AUTOSAR XML (schema 4-2-2)
package /ComponentTypes
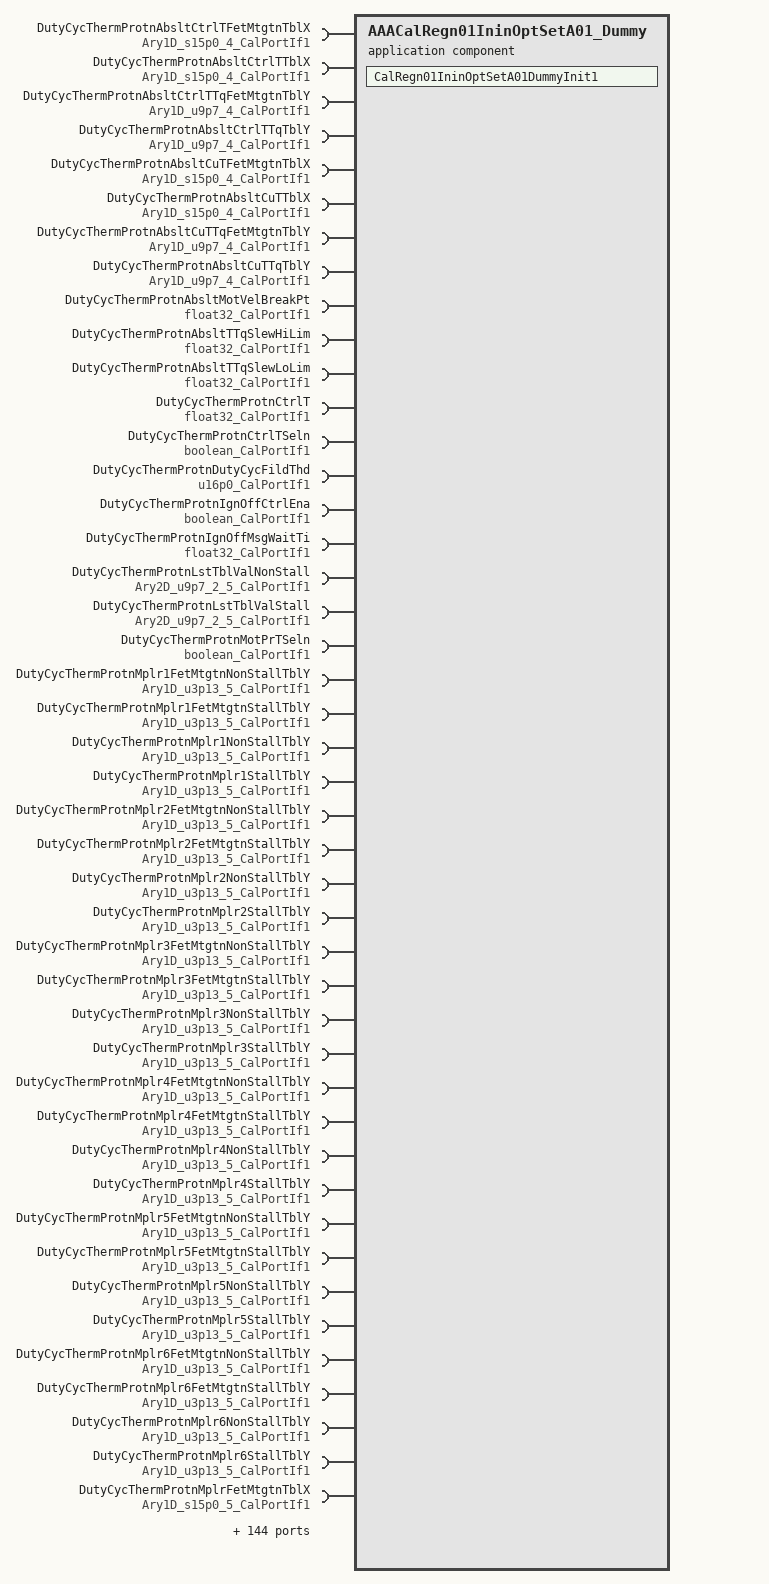
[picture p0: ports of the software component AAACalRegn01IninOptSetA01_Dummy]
  application sw component type AAACalRegn01IninOptSetA01_Dummy
    188 x require port:
      DutyCycThermProtnAbsltCtrlTFetMtgtnTblX: parameter-require-com-spec{init-value=[122, 123, 125, 127], parameter=Ary1D}, required-interface=Ary1D_s15p0_4_CalPortIf1
      DutyCycThermProtnAbsltCtrlTTblX: parameter-require-com-spec{init-value=[122, 123, 125, 127], parameter=Ary1D}, required-interface=Ary1D_s15p0_4_CalPortIf1
      DutyCycThermProtnAbsltCtrlTTqFetMtgtnTblY: parameter-require-com-spec{init-value=[346, 287, 234, 0], parameter=Ary1D}, required-interface=Ary1D_u9p7_4_CalPortIf1
      DutyCycThermProtnAbsltCtrlTTqTblY: parameter-require-com-spec{init-value=[346, 287, 234, 0], parameter=Ary1D}, required-interface=Ary1D_u9p7_4_CalPortIf1
      DutyCycThermProtnAbsltCuTFetMtgtnTblX: parameter-require-com-spec{init-value=[122, 123, 125, 127], parameter=Ary1D}, required-interface=Ary1D_s15p0_4_CalPortIf1
      DutyCycThermProtnAbsltCuTTblX: parameter-require-com-spec{init-value=[122, 123, 125, 127], parameter=Ary1D}, required-interface=Ary1D_s15p0_4_CalPortIf1
      DutyCycThermProtnAbsltCuTTqFetMtgtnTblY: parameter-require-com-spec{init-value=[346, 287, 234, 0], parameter=Ary1D}, required-interface=Ary1D_u9p7_4_CalPortIf1
      DutyCycThermProtnAbsltCuTTqTblY: parameter-require-com-spec{init-value=[346, 287, 234, 0], parameter=Ary1D}, required-interface=Ary1D_u9p7_4_CalPortIf1
      DutyCycThermProtnAbsltMotVelBreakPt: parameter-require-com-spec{init-value=1.375, parameter=Val}, required-interface=float32_CalPortIf1
      DutyCycThermProtnAbsltTTqSlewHiLim: parameter-require-com-spec{init-value=0.3, parameter=Val}, required-interface=float32_CalPortIf1
      DutyCycThermProtnAbsltTTqSlewLoLim: parameter-require-com-spec{init-value=0.3, parameter=Val}, required-interface=float32_CalPortIf1
      DutyCycThermProtnCtrlT: parameter-require-com-spec{init-value=70, parameter=Val}, required-interface=float32_CalPortIf1
      DutyCycThermProtnCtrlTSeln: parameter-require-com-spec{init-value=1, parameter=Logl}, required-interface=boolean_CalPortIf1
      DutyCycThermProtnDutyCycFildThd: parameter-require-com-spec{init-value=92, parameter=Val}, required-interface=u16p0_CalPortIf1
      DutyCycThermProtnIgnOffCtrlEna: parameter-require-com-spec{init-value=0, parameter=Logl}, required-interface=boolean_CalPortIf1
      DutyCycThermProtnIgnOffMsgWaitTi: parameter-require-com-spec{init-value=0.5, parameter=Val}, required-interface=float32_CalPortIf1
      DutyCycThermProtnLstTblValNonStall: parameter-require-com-spec{init-value=[[128, 128, 128, 44, 44], [128, 128, 128, 44, 44]], parameter=Ary2D}, required-interface=Ary2D_u9p7_2_5_CalPortIf1
      DutyCycThermProtnLstTblValStall: parameter-require-com-spec{init-value=[[124, 124, 124, 40, 40], [124, 124, 124, 40, 40]], parameter=Ary2D}, required-interface=Ary2D_u9p7_2_5_CalPortIf1
      DutyCycThermProtnMotPrTSeln: parameter-require-com-spec{init-value=1, parameter=Logl}, required-interface=boolean_CalPortIf1
      DutyCycThermProtnMplr1FetMtgtnNonStallTblY: parameter-require-com-spec{init-value=[127, 127, 127, 1630, 1630], parameter=Ary1D}, required-interface=Ary1D_u3p13_5_CalPortIf1
      DutyCycThermProtnMplr1FetMtgtnStallTblY: parameter-require-com-spec{init-value=[133, 133, 133, 180, 180], parameter=Ary1D}, required-interface=Ary1D_u3p13_5_CalPortIf1
      DutyCycThermProtnMplr1NonStallTblY: parameter-require-com-spec{init-value=[127, 127, 127, 1630, 1630], parameter=Ary1D}, required-interface=Ary1D_u3p13_5_CalPortIf1
      DutyCycThermProtnMplr1StallTblY: parameter-require-com-spec{init-value=[133, 133, 133, 180, 180], parameter=Ary1D}, required-interface=Ary1D_u3p13_5_CalPortIf1
      DutyCycThermProtnMplr2FetMtgtnNonStallTblY: parameter-require-com-spec{init-value=[159, 159, 159, 281, 281], parameter=Ary1D}, required-interface=Ary1D_u3p13_5_CalPortIf1
      DutyCycThermProtnMplr2FetMtgtnStallTblY: parameter-require-com-spec{init-value=[167, 167, 167, 310, 310], parameter=Ary1D}, required-interface=Ary1D_u3p13_5_CalPortIf1
      DutyCycThermProtnMplr2NonStallTblY: parameter-require-com-spec{init-value=[159, 159, 159, 281, 281], parameter=Ary1D}, required-interface=Ary1D_u3p13_5_CalPortIf1
      DutyCycThermProtnMplr2StallTblY: parameter-require-com-spec{init-value=[167, 167, 167, 310, 310], parameter=Ary1D}, required-interface=Ary1D_u3p13_5_CalPortIf1
      DutyCycThermProtnMplr3FetMtgtnNonStallTblY: parameter-require-com-spec{init-value=[199, 199, 199, 1282, 1282], parameter=Ary1D}, required-interface=Ary1D_u3p13_5_CalPortIf1
      DutyCycThermProtnMplr3FetMtgtnStallTblY: parameter-require-com-spec{init-value=[210, 210, 210, 1707, 1707], parameter=Ary1D}, required-interface=Ary1D_u3p13_5_CalPortIf1
      DutyCycThermProtnMplr3NonStallTblY: parameter-require-com-spec{init-value=[199, 199, 199, 1282, 1282], parameter=Ary1D}, required-interface=Ary1D_u3p13_5_CalPortIf1
      DutyCycThermProtnMplr3StallTblY: parameter-require-com-spec{init-value=[210, 210, 210, 1707, 1707], parameter=Ary1D}, required-interface=Ary1D_u3p13_5_CalPortIf1
      DutyCycThermProtnMplr4FetMtgtnNonStallTblY: parameter-require-com-spec{init-value=5 x 1, parameter=Ary1D}, required-interface=Ary1D_u3p13_5_CalPortIf1
      DutyCycThermProtnMplr4FetMtgtnStallTblY: parameter-require-com-spec{init-value=5 x 1, parameter=Ary1D}, required-interface=Ary1D_u3p13_5_CalPortIf1
      DutyCycThermProtnMplr4NonStallTblY: parameter-require-com-spec{init-value=5 x 1, parameter=Ary1D}, required-interface=Ary1D_u3p13_5_CalPortIf1
      DutyCycThermProtnMplr4StallTblY: parameter-require-com-spec{init-value=5 x 1, parameter=Ary1D}, required-interface=Ary1D_u3p13_5_CalPortIf1
      DutyCycThermProtnMplr5FetMtgtnNonStallTblY: parameter-require-com-spec{init-value=[998, 998, 998, 9535, 9535], parameter=Ary1D}, required-interface=Ary1D_u3p13_5_CalPortIf1
      DutyCycThermProtnMplr5FetMtgtnStallTblY: parameter-require-com-spec{init-value=[998, 998, 998, 9535, 9535], parameter=Ary1D}, required-interface=Ary1D_u3p13_5_CalPortIf1
      DutyCycThermProtnMplr5NonStallTblY: parameter-require-com-spec{init-value=[998, 998, 998, 9535, 9535], parameter=Ary1D}, required-interface=Ary1D_u3p13_5_CalPortIf1
      DutyCycThermProtnMplr5StallTblY: parameter-require-com-spec{init-value=[998, 998, 998, 9535, 9535], parameter=Ary1D}, required-interface=Ary1D_u3p13_5_CalPortIf1
      DutyCycThermProtnMplr6FetMtgtnNonStallTblY: parameter-require-com-spec{init-value=5 x 1, parameter=Ary1D}, required-interface=Ary1D_u3p13_5_CalPortIf1
      DutyCycThermProtnMplr6FetMtgtnStallTblY: parameter-require-com-spec{init-value=5 x 1, parameter=Ary1D}, required-interface=Ary1D_u3p13_5_CalPortIf1
      DutyCycThermProtnMplr6NonStallTblY: parameter-require-com-spec{init-value=5 x 1, parameter=Ary1D}, required-interface=Ary1D_u3p13_5_CalPortIf1
      DutyCycThermProtnMplr6StallTblY: parameter-require-com-spec{init-value=5 x 1, parameter=Ary1D}, required-interface=Ary1D_u3p13_5_CalPortIf1
      DutyCycThermProtnMplrFetMtgtnTblX: parameter-require-com-spec{init-value=[-40, 0, 83, 84, 85], parameter=Ary1D}, required-interface=Ary1D_s15p0_5_CalPortIf1
      DutyCycThermProtnMplrTblX: parameter-require-com-spec{init-value=[-40, 0, 83, 84, 85], parameter=Ary1D}, required-interface=Ary1D_s15p0_5_CalPortIf1
      DutyCycThermProtnMplrTSeln: parameter-require-com-spec{init-value=1, parameter=Logl}, required-interface=boolean_CalPortIf1
      DutyCycThermProtnSlowFilTSeln: parameter-require-com-spec{init-value=0, parameter=Logl}, required-interface=boolean_CalPortIf1
      DutyCycThermProtnThermLimScaFac: parameter-require-com-spec{init-value=0.5, parameter=Val}, required-interface=float32_CalPortIf1
      DutyCycThermProtnThermLoadLimTblX: parameter-require-com-spec{init-value=[[0, 76, 80, 84, 88, 92, 96, 100], [0, 76, 80, 84, 88, 92, 96, 100]], parameter=Ary2D}, required-interface=Ary2D_u16p0_2_8_CalPortIf1
      DutyCycThermProtnThermLoadLimTblY: parameter-require-com-spec{init-value=[[346, 346, 346, 346, 287, 234, 181, 128], [346, 346, 346, 346, 287, 234, 181, 128]], parameter=Ary2D}, required-interface=Ary2D_u9p7_2_8_CalPortIf1
      DutyCycThermProtnTqCmdSlewDwn: parameter-require-com-spec{init-value=0.3, parameter=Val}, required-interface=float32_CalPortIf1
      DutyCycThermProtnTqCmdSlewUp: parameter-require-com-spec{init-value=0.3, parameter=Val}, required-interface=float32_CalPortIf1
      HiLoadStallLimrMotVelMgnThd: parameter-require-com-spec{init-value=[1.375, 1.375], parameter=Ary1D}, required-interface=Ary1D_f32_2_CalPortIf1
      HiLoadStallLimrStallMotTqCmdFetMtgtnLimX: parameter-require-com-spec{init-value=[0, 563, 640, 717, 768, 768], parameter=Ary1D}, required-interface=Ary1D_u8p8_6_CalPortIf1
      HiLoadStallLimrStallMotTqCmdFetMtgtnLimY: parameter-require-com-spec{init-value=[768, 768, 512, 256, 0, 0], parameter=Ary1D}, required-interface=Ary1D_u8p8_6_CalPortIf1
      HiLoadStallLimrStallMotTqCmdLimX: parameter-require-com-spec{init-value=[0, 563, 640, 717, 768, 768], parameter=Ary1D}, required-interface=Ary1D_u8p8_6_CalPortIf1
      HiLoadStallLimrStallMotTqCmdLimY: parameter-require-com-spec{init-value=[768, 768, 512, 256, 0, 0], parameter=Ary1D}, required-interface=Ary1D_u8p8_6_CalPortIf1
      HiLoadStallLimrStallMotTqLimSlewRate: parameter-require-com-spec{init-value=[0.101563, 0.101563], parameter=Ary1D}, required-interface=Ary1D_f32_2_CalPortIf1
      HiLoadStallLimrStallThermLimSca: parameter-require-com-spec{init-value=0.5, parameter=Val}, required-interface=float32_CalPortIf1
      LrndRackCentrMotTqThd: parameter-require-com-spec{init-value=2.8, parameter=Val}, required-interface=float32_CalPortIf1
      LrndRackCentrMotVelThd: parameter-require-com-spec{init-value=25, parameter=Val}, required-interface=float32_CalPortIf1
      MotCtrlPrmEstimnFetRNom: parameter-require-com-spec{init-value=0.0052, parameter=Val}, required-interface=float32_CalPortIf1
      MotCtrlPrmEstimnMotBackEmfConHiLim: parameter-require-com-spec{init-value=0.045, parameter=Val}, required-interface=float32_CalPortIf1
      MotCtrlPrmEstimnMotBackEmfConLoLim: parameter-require-com-spec{init-value=0.031, parameter=Val}, required-interface=float32_CalPortIf1
      MotCtrlPrmEstimnMotBackEmfConNom: parameter-require-com-spec{init-value=0.04, parameter=Val}, required-interface=float32_CalPortIf1
      MotCtrlPrmEstimnMotBackEmfConSatnScaIvtrLoaMtgtn: parameter-require-com-spec{init-value=1, parameter=Val}, required-interface=float32_CalPortIf1
      MotCtrlPrmEstimnMotBackEmfConSatnX: parameter-require-com-spec{init-value=[0, 1280, 2560, 3840, 5120, 6400, 7680, 8960, 10240, 11520, 12800, 14080, 15360, 16640, 19200, 21760], parameter=Ary1D}, required-interface=Ary1D_u9p7_16_CalPortIf1
      MotCtrlPrmEstimnMotBackEmfConSatnY: parameter-require-com-spec{init-value=[16384, 16384, 16384, 16384, 16384, 16384, 16384, 16384, 16384, 16384, 16384, 16370, 16336, 16276, 16095, 15869], parameter=Ary1D}, required-interface=Ary1D_u2p14_16_CalPortIf1
      MotCtrlPrmEstimnMotCurrDaxInduSatnBilnrSeln: parameter-require-com-spec{init-value=[0, 3200, 6400, 9600, 12800, 16000], parameter=Ary1D}, required-interface=Ary1D_u9p7_6_CalPortIf1
      MotCtrlPrmEstimnMotCurrQaxInduSatnX: parameter-require-com-spec{init-value=[0, 3200, 6400, 9600, 12800, 16000, 19200], parameter=Ary1D}, required-interface=Ary1D_u9p7_7_CalPortIf1
      MotCtrlPrmEstimnMotInduDaxHiLim: parameter-require-com-spec{init-value=0.00013, parameter=Val}, required-interface=float32_CalPortIf1
      MotCtrlPrmEstimnMotInduDaxIvtrLoaMtgtn: parameter-require-com-spec{init-value=0.00013, parameter=Val}, required-interface=float32_CalPortIf1
      MotCtrlPrmEstimnMotInduDaxLoLim: parameter-require-com-spec{init-value=0.0001, parameter=Val}, required-interface=float32_CalPortIf1
      MotCtrlPrmEstimnMotInduDaxNom: parameter-require-com-spec{init-value=0.00011889, parameter=Val}, required-interface=float32_CalPortIf1
      MotCtrlPrmEstimnMotInduDaxSatnScaY: parameter-require-com-spec{init-value=6 x [16384, 16384, 16384, 16384, 16384, 16305, 16096], parameter=Ary2D}, required-interface=Ary2D_u2p14_6_7_CalPortIf1
      MotCtrlPrmEstimnMotInduQaxHiLim: parameter-require-com-spec{init-value=0.00013, parameter=Val}, required-interface=float32_CalPortIf1
      MotCtrlPrmEstimnMotInduQaxIvtrLoaMtgtn: parameter-require-com-spec{init-value=0.00013, parameter=Val}, required-interface=float32_CalPortIf1
      MotCtrlPrmEstimnMotInduQaxLoLim: parameter-require-com-spec{init-value=0.0001, parameter=Val}, required-interface=float32_CalPortIf1
      MotCtrlPrmEstimnMotInduQaxNom: parameter-require-com-spec{init-value=0.00011889, parameter=Val}, required-interface=float32_CalPortIf1
      MotCtrlPrmEstimnMotInduQaxSatnScaY: parameter-require-com-spec{init-value=6 x [16384, 16384, 16384, 16384, 16384, 16305, 16096], parameter=Ary2D}, required-interface=Ary2D_u2p14_6_7_CalPortIf1
      MotCtrlPrmEstimnMotRHiLim: parameter-require-com-spec{init-value=0.032, parameter=Val}, required-interface=float32_CalPortIf1
      MotCtrlPrmEstimnMotRLoLim: parameter-require-com-spec{init-value=0.01246, parameter=Val}, required-interface=float32_CalPortIf1
      MotCtrlPrmEstimnMotRNom: parameter-require-com-spec{init-value=0.0139, parameter=Val}, required-interface=float32_CalPortIf1
      MotCtrlPrmEstimnMotWidgThermCoeff: parameter-require-com-spec{init-value=0.0039, parameter=Val}, required-interface=float32_CalPortIf1
      MotCtrlPrmEstimnTNom: parameter-require-com-spec{init-value=25, parameter=Val}, required-interface=float32_CalPortIf1
      MotCurrPeakEstimnCurrFilFrq: parameter-require-com-spec{init-value=8, parameter=Val}, required-interface=float32_CalPortIf1
      MotCurrPeakEstimnCurrPeakEstimdFilFrq: parameter-require-com-spec{init-value=0.03, parameter=Val}, required-interface=float32_CalPortIf1
      MotCurrRegCfgMotClsdLoopBwDaxY: parameter-require-com-spec{init-value=[12800, 19200, 19200, 19200], parameter=Ary1D}, required-interface=Ary1D_u10p6_4_CalPortIf1
      MotCurrRegCfgMotClsdLoopBwQaxY: parameter-require-com-spec{init-value=[12800, 19200, 19200, 19200], parameter=Ary1D}, required-interface=Ary1D_u10p6_4_CalPortIf1
      MotCurrRegCfgMotDampgRatDax: parameter-require-com-spec{init-value=1, parameter=Val}, required-interface=float32_CalPortIf1
      MotCurrRegCfgMotDampgRatQax: parameter-require-com-spec{init-value=1, parameter=Val}, required-interface=float32_CalPortIf1
      MotCurrRegCfgMotNatFrqDaxY: parameter-require-com-spec{init-value=[38400, 38400, 38400, 38400], parameter=Ary1D}, required-interface=Ary1D_u9p7_4_CalPortIf1
      MotCurrRegCfgMotNatFrqQaxY: parameter-require-com-spec{init-value=[38400, 38400, 38400, 38400], parameter=Ary1D}, required-interface=Ary1D_u9p7_4_CalPortIf1
      MotCurrRegCfgMotRVirtDax: parameter-require-com-spec{init-value=0, parameter=Val}, required-interface=float32_CalPortIf1
      MotCurrRegCfgMotRVirtQax: parameter-require-com-spec{init-value=0, parameter=Val}, required-interface=float32_CalPortIf1
      MotCurrRegCfgMotVelFilFrq: parameter-require-com-spec{init-value=10, parameter=Val}, required-interface=float32_CalPortIf1
      MotCurrRegVltgLimrCurrLoaScarSlewRate: parameter-require-com-spec{init-value=100, parameter=Val}, required-interface=float32_CalPortIf1
      MotCurrRegVltgLimrDaxAntiWdupCoeff: parameter-require-com-spec{init-value=0, parameter=Val}, required-interface=float32_CalPortIf1
      MotCurrRegVltgLimrDualEcuLoaScarSlewRate: parameter-require-com-spec{init-value=100, parameter=Val}, required-interface=float32_CalPortIf1
      MotCurrRegVltgLimrFETLoaScarSlewRate: parameter-require-com-spec{init-value=100, parameter=Val}, required-interface=float32_CalPortIf1
      MotCurrRegVltgLimrIvtrLoaScarSlewRate: parameter-require-com-spec{init-value=100, parameter=Val}, required-interface=float32_CalPortIf1
      MotCurrRegVltgLimrMotVltgBrdgLpFilFrq: parameter-require-com-spec{init-value=200, parameter=Val}, required-interface=float32_CalPortIf1
      MotCurrRegVltgLimrMotVltgDaxIntglHiLim: parameter-require-com-spec{init-value=9, parameter=Val}, required-interface=float32_CalPortIf1
      MotCurrRegVltgLimrMotVltgDaxIntglLoLim: parameter-require-com-spec{init-value=-4.5, parameter=Val}, required-interface=float32_CalPortIf1
      MotCurrRegVltgLimrMotVltgQaxFfLpFilFrq: parameter-require-com-spec{init-value=500, parameter=Val}, required-interface=float32_CalPortIf1
      MotCurrRegVltgLimrMotVltgQaxIntglHiLim: parameter-require-com-spec{init-value=14.5, parameter=Val}, required-interface=float32_CalPortIf1
      MotCurrRegVltgLimrMotVltgQaxIntglLoLim: parameter-require-com-spec{init-value=-14.5, parameter=Val}, required-interface=float32_CalPortIf1
      MotCurrRegVltgLimrQaxAntiWdupCoeff: parameter-require-com-spec{init-value=0, parameter=Val}, required-interface=float32_CalPortIf1
      MotCurrRegVltgLimrQaxAntiWdupScagDi: parameter-require-com-spec{init-value=0, parameter=Logl}, required-interface=boolean_CalPortIf1
      MotRefMdlCurrDaxBoostGain: parameter-require-com-spec{init-value=0, parameter=Val}, required-interface=float32_CalPortIf1
      MotRefMdlCurrDaxBoostTqScaX: parameter-require-com-spec{init-value=[0, 6144, 7168, 8192, 9216, 10240, 12288, 14336, 16384, 18432, 20480], parameter=Ary1D}, required-interface=Ary1D_u4p12_11_CalPortIf1
      MotRefMdlCurrDaxBoostTqScaY: parameter-require-com-spec{init-value=[0, 16384, 19661, 22938, 23757, 25395, 27034, 27853, 29491, 31130, 32768], parameter=Ary1D}, required-interface=Ary1D_u1p15_11_CalPortIf1
      MotRefMdlCurrDaxQaxRefDelta: parameter-require-com-spec{init-value=[-3.1415927, -2.3561945, -1.5707964, -0.7853982, 0, 0.7853982, 1.5707964, 2.3561945], parameter=Ary1D}, required-interface=Ary1D_f32_8_CalPortIf1
      MotRefMdlCurrItrnTolr: parameter-require-com-spec{init-value=0.1, parameter=Val}, required-interface=float32_CalPortIf1
      MotRefMdlMotCurrDaxMaxSca: parameter-require-com-spec{init-value=1, parameter=Val}, required-interface=float32_CalPortIf1
      MotRefMdlQuad13VltgSdlX: parameter-require-com-spec{init-value=[0, 3200, 6400, 9600, 16000, 19200, 22400, 25600, 28800, 35200], parameter=Ary1D}, required-interface=Ary1D_u11p5_10_CalPortIf1
      MotRefMdlQuad13VltgSdlY: parameter-require-com-spec{init-value=10 x 0, parameter=Ary1D}, required-interface=Ary1D_u3p13_10_CalPortIf1
      MotRefMdlQuad24VltgSdlX: parameter-require-com-spec{init-value=[0, 3200, 6400, 9600, 16000, 19200, 22400, 25600, 28800, 35200], parameter=Ary1D}, required-interface=Ary1D_u11p5_10_CalPortIf1
      MotRefMdlQuad24VltgSdlY: parameter-require-com-spec{init-value=10 x 0, parameter=Ary1D}, required-interface=Ary1D_u3p13_10_CalPortIf1
      MotRefMdlVltgOverRThdSca: parameter-require-com-spec{init-value=0.25, parameter=Val}, required-interface=float32_CalPortIf1
      MotTqTranlDampgCmdLim: parameter-require-com-spec{init-value=3, parameter=Val}, required-interface=float32_CalPortIf1
      MotTqTranlDampgVelThd: parameter-require-com-spec{init-value=2.3, parameter=Val}, required-interface=float32_CalPortIf1
      PwrLimrAssiRednLpFilFrq: parameter-require-com-spec{init-value=0.365, parameter=Val}, required-interface=float32_CalPortIf1
      PwrLimrBackEmfConStdT: parameter-require-com-spec{init-value=0.0335999, parameter=Val}, required-interface=float32_CalPortIf1
      PwrLimrBrdgVltgAdjSlew: parameter-require-com-spec{init-value=0.5, parameter=Val}, required-interface=float32_CalPortIf1
      PwrLimrBrdgVltgAltFltAdj: parameter-require-com-spec{init-value=1, parameter=Val}, required-interface=float32_CalPortIf1
      PwrLimrFilAssiRednThd: parameter-require-com-spec{init-value=0.6, parameter=Val}, required-interface=float32_CalPortIf1
      PwrLimrLoVoltAssiRcvrThd: parameter-require-com-spec{init-value=13.5, parameter=Val}, required-interface=float32_CalPortIf1
      PwrLimrLoVoltAssiRcvrTi: parameter-require-com-spec{init-value=2000, parameter=Val}, required-interface=uint16_CalPortIf1
      PwrLimrMotEnvlpX: parameter-require-com-spec{init-value=[-17600, -12800, -10400, -8800, -5657, -4600, -3499, -1731, 0, 1731, 3499, 4600, 5657, 8800], parameter=Ary1D}, required-interface=Ary1D_s11p4_14_CalPortIf1
      PwrLimrMotEnvlpY: parameter-require-com-spec{init-value=[1475, 2867, 3891, 4710, 7168, 8397, 9486, 9486, 9486, 9486, 7277, 5994, 4506, 0], parameter=Ary1D}, required-interface=Ary1D_u5p11_14_CalPortIf1
      PwrLimrMotVelLpFilFrq: parameter-require-com-spec{init-value=100, parameter=Val}, required-interface=float32_CalPortIf1
      PwrLimrSpdAdjSlewDec: parameter-require-com-spec{init-value=3.125, parameter=Val}, required-interface=float32_CalPortIf1
      PwrLimrSpdAdjSlewEna: parameter-require-com-spec{init-value=1, parameter=Logl}, required-interface=boolean_CalPortIf1
      PwrLimrSpdAdjSlewInc: parameter-require-com-spec{init-value=3125, parameter=Val}, required-interface=float32_CalPortIf1
      PwrLimrStdOperMotEnvlpX: parameter-require-com-spec{init-value=[0, 2182, 5717, 7919, 10034, 16320], parameter=Ary1D}, required-interface=Ary1D_u11p5_6_CalPortIf1
      PwrLimrStdOperMotEnvlpY: parameter-require-com-spec{init-value=[18973, 18973, 14553, 11989, 9011, 0], parameter=Ary1D}, required-interface=Ary1D_u4p12_6_CalPortIf1
      PwrLimrVltgDptMotVelOffsX: parameter-require-com-spec{init-value=[17496, 18728, 18928, 19136, 19336, 19544, 20568, 21592, 22208, 25280], parameter=Ary1D}, required-interface=Ary1D_u5p11_10_CalPortIf1
      PwrLimrVltgDptMotVelOffsY: parameter-require-com-spec{init-value=[3395, 2859, 2769, 2680, 2591, 2501, 2054, 1608, 1340, 0], parameter=Ary1D}, required-interface=Ary1D_u11p5_10_CalPortIf1
      SysGlbPrmSysTqRat: parameter-require-com-spec{init-value=20, parameter=Val}, required-interface=float32_CalPortIf1
      TEstimnAmbPwrMplr: parameter-require-com-spec{init-value=[0.01, 0.01, 0.01], parameter=Ary1D}, required-interface=Ary1D_f32_3_CalPortIf1
      TEstimnAmbTSca: parameter-require-com-spec{init-value=[0.9, 0.9, 0.9], parameter=Ary1D}, required-interface=Ary1D_f32_3_CalPortIf1
      TEstimnAssiMechAmbLpFilFrq: parameter-require-com-spec{init-value=0.024, parameter=Val}, required-interface=float32_CalPortIf1
      TEstimnAssiMechAmbLpFilFrqDualEcuFltMtgtn: parameter-require-com-spec{init-value=0.024, parameter=Val}, required-interface=float32_CalPortIf1
      TEstimnAssiMechAmbLpFilFrqFetMtgtnEna: parameter-require-com-spec{init-value=0.024, parameter=Val}, required-interface=float32_CalPortIf1
      TEstimnAssiMechAmbMplr: parameter-require-com-spec{init-value=[0.01, 0.01, 0.01], parameter=Ary1D}, required-interface=Ary1D_f32_3_CalPortIf1
      TEstimnAssiMechCorrLim: parameter-require-com-spec{init-value=[60, 60, 60], parameter=Ary1D}, required-interface=Ary1D_f32_3_CalPortIf1
      TEstimnAssiMechDampgSca: parameter-require-com-spec{init-value=[0.0001, 0.0001, 0.0001], parameter=Ary1D}, required-interface=Ary1D_f32_3_CalPortIf1
      TEstimnAssiMechDftT: parameter-require-com-spec{init-value=[50, 50, 50], parameter=Ary1D}, required-interface=Ary1D_f32_3_CalPortIf1
      TEstimnAssiMechLLFilCoeffA1: parameter-require-com-spec{init-value=[0.99996858, 0.99996858, 0.99996858], parameter=Ary1D}, required-interface=Ary1D_f32_3_CalPortIf1
      TEstimnAssiMechLLFilCoeffB0: parameter-require-com-spec{init-value=[0.4761987, 0.4761987, 0.4761987], parameter=Ary1D}, required-interface=Ary1D_f32_3_CalPortIf1
      TEstimnAssiMechLLFilCoeffB1: parameter-require-com-spec{init-value=[-0.4761673, -0.4761673, -0.4761673], parameter=Ary1D}, required-interface=Ary1D_f32_3_CalPortIf1
      TEstimnAssiMechSlew: parameter-require-com-spec{init-value=[1, 1, 1], parameter=Ary1D}, required-interface=Ary1D_f32_3_CalPortIf1
      TEstimnCorrnTAssiMech: parameter-require-com-spec{init-value=[0, 0, 0], parameter=Ary1D}, required-interface=Ary1D_f32_3_CalPortIf1
      TEstimnCorrnTCu: parameter-require-com-spec{init-value=[0, 0, 0], parameter=Ary1D}, required-interface=Ary1D_f32_3_CalPortIf1
      TEstimnCorrnTMag: parameter-require-com-spec{init-value=[0, 0, 0], parameter=Ary1D}, required-interface=Ary1D_f32_3_CalPortIf1
      TEstimnCorrnTSi: parameter-require-com-spec{init-value=[0, 0, 0], parameter=Ary1D}, required-interface=Ary1D_f32_3_CalPortIf1
      TEstimnCuAmbLpFilFrq: parameter-require-com-spec{init-value=0.024, parameter=Val}, required-interface=float32_CalPortIf1
      TEstimnCuAmbLpFilFrqDualEcuFltMtgtn: parameter-require-com-spec{init-value=0.024, parameter=Val}, required-interface=float32_CalPortIf1
      TEstimnCuAmbLpFilFrqFetMtgtnEna: parameter-require-com-spec{init-value=0.024, parameter=Val}, required-interface=float32_CalPortIf1
      TEstimnCuAmbMplr: parameter-require-com-spec{init-value=[0.75, 0.75, 0.75], parameter=Ary1D}, required-interface=Ary1D_f32_3_CalPortIf1
      TEstimnCuCorrnLim: parameter-require-com-spec{init-value=[80, 80, 80], parameter=Ary1D}, required-interface=Ary1D_f32_3_CalPortIf1
      TEstimnCuLLFilCoeffA1: parameter-require-com-spec{init-value=[0.999943, 0.999943, 0.999943], parameter=Ary1D}, required-interface=Ary1D_f32_3_CalPortIf1
      TEstimnCuLLFilCoeffB0: parameter-require-com-spec{init-value=[0.86667, 0.86667, 0.86667], parameter=Ary1D}, required-interface=Ary1D_f32_3_CalPortIf1
      TEstimnCuLLFilCoeffB1: parameter-require-com-spec{init-value=[-0.866613, -0.866613, -0.866613], parameter=Ary1D}, required-interface=Ary1D_f32_3_CalPortIf1
      TEstimnEngTSca: parameter-require-com-spec{init-value=[0.1, 0.1, 0.1], parameter=Ary1D}, required-interface=Ary1D_f32_3_CalPortIf1
      TEstimnMagAmbLpFilFrq: parameter-require-com-spec{init-value=0.024, parameter=Val}, required-interface=float32_CalPortIf1
      TEstimnMagAmbLpFilFrqDualEcuFltMtgtn: parameter-require-com-spec{init-value=0.024, parameter=Val}, required-interface=float32_CalPortIf1
      TEstimnMagAmbLpFilFrqFetMtgtnEna: parameter-require-com-spec{init-value=0.024, parameter=Val}, required-interface=float32_CalPortIf1
      TEstimnMagAmbMplr: parameter-require-com-spec{init-value=[0.01, 0.01, 0.01], parameter=Ary1D}, required-interface=Ary1D_f32_3_CalPortIf1
      TEstimnMagCorrnLim: parameter-require-com-spec{init-value=[60, 60, 60], parameter=Ary1D}, required-interface=Ary1D_f32_3_CalPortIf1
      TEstimnMagLLFilCoeffA1: parameter-require-com-spec{init-value=[0.999962, 0.999962, 0.999962], parameter=Ary1D}, required-interface=Ary1D_f32_3_CalPortIf1
      TEstimnMagLLFilCoeffB0: parameter-require-com-spec{init-value=[0.571437, 0.571437, 0.571437], parameter=Ary1D}, required-interface=Ary1D_f32_3_CalPortIf1
      TEstimnMagLLFilCoeffB1: parameter-require-com-spec{init-value=[-0.571399, -0.571399, -0.571399], parameter=Ary1D}, required-interface=Ary1D_f32_3_CalPortIf1
      TEstimnSiAmbLpFilFrq: parameter-require-com-spec{init-value=0.024, parameter=Val}, required-interface=float32_CalPortIf1
      TEstimnSiAmbLpFilFrqDualEcuFltMtgtn: parameter-require-com-spec{init-value=0.024, parameter=Val}, required-interface=float32_CalPortIf1
      TEstimnSiAmbLpFilFrqFetMtgtnEna: parameter-require-com-spec{init-value=0.024, parameter=Val}, required-interface=float32_CalPortIf1
      TEstimnSiAmbMplr: parameter-require-com-spec{init-value=[0, 0, 0], parameter=Ary1D}, required-interface=Ary1D_f32_3_CalPortIf1
      TEstimnSiCorrnLim: parameter-require-com-spec{init-value=[60, 60, 60], parameter=Ary1D}, required-interface=Ary1D_f32_3_CalPortIf1
      TEstimnSiLLFilCoeffA1: parameter-require-com-spec{init-value=[0.999889, 0.999889, 0.999889], parameter=Ary1D}, required-interface=Ary1D_f32_3_CalPortIf1
      TEstimnSiLLFilCoeffB0: parameter-require-com-spec{init-value=[1.68568, 1.68568, 1.68568], parameter=Ary1D}, required-interface=Ary1D_f32_3_CalPortIf1
      TEstimnSiLLFilCoeffB1: parameter-require-com-spec{init-value=[-1.68556, -1.68556, -1.68556], parameter=Ary1D}, required-interface=Ary1D_f32_3_CalPortIf1
      TEstimnTauAssiMech: parameter-require-com-spec{init-value=[4000, 4000, 4000], parameter=Ary1D}, required-interface=Ary1D_f32_3_CalPortIf1
      TEstimnTauCu: parameter-require-com-spec{init-value=[79, 79, 79], parameter=Ary1D}, required-interface=Ary1D_f32_3_CalPortIf1
      TEstimnTauMag: parameter-require-com-spec{init-value=[50, 50, 50], parameter=Ary1D}, required-interface=Ary1D_f32_3_CalPortIf1
      TEstimnTauSi: parameter-require-com-spec{init-value=[214, 214, 214], parameter=Ary1D}, required-interface=Ary1D_f32_3_CalPortIf1
      TEstimnWghtAvrgTDi: parameter-require-com-spec{init-value=[0, 0, 0], parameter=Ary1D}, required-interface=Ary1D_logl_3_CalPortIf1
      VehSpdLimrPosMaxOffs2: parameter-require-com-spec{init-value=120, parameter=Val}, required-interface=float32_CalPortIf1
    behavior AAACalRegn01IninOptSetA01_Dummy_InternalBehavior: supports-multiple-instantiation=true
      init event AAACalRegn01IninOptSetA01_Dummy_InitEvent: start-on-event=CalRegn01IninOptSetA01DummyInit1
      runnable CalRegn01IninOptSetA01DummyInit1
  swc implementation AAACalRegn01IninOptSetA00_Dummy_Implementation: behavior=AAACalRegn01IninOptSetA01_Dummy_InternalBehavior
    code-descriptors:
      code Default: artifact-descriptors=autosar-engineering-object={short-label=Default, category=SWSRC}
